# MSPM0G150X register map
Vendor: Texas Instruments; File version: This preliminary header file does not have a version number - build date: 2024-04-29 21:43:54
CPU: CM0 r0p1, little endian, MPU, no FPU, 3 interrupt priority bits
Registers are 32-bit, read-write, reset 0x0 unless marked. A register's access mark holds for its fields unless they carry their own. Offsets are from the block's base; [hi:lo] are bit positions; lines under a group give offsets from that group; {n}, {i} and the like mark numbered series; 'fields as' and 'values as' point back to an identical list.

## RTC — PERIPHERALREGION
Base 0x40094000
0x444 RTC_FPUB_0 — Publisher Port 0
  [3:0] CHANID — 0 = disconnected. 1-15 = connected to channelID = CHANID.
    0=UNCONNECTED (A value of 0 specifies that the event is not connected)
{0x800+0x18*i} RTC_GPRCM[{i}] (i=0..0) group
  0x00 RTC_PWREN — Power enable
    [0] ENABLE — Enable the power
      0=DISABLE (Disable Power); 1=ENABLE (Enable Power)
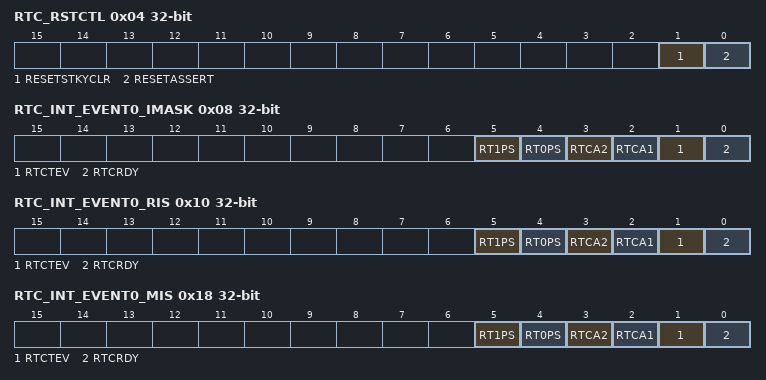
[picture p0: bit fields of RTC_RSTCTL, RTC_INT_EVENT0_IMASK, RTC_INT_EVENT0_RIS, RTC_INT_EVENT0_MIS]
  0x04 RTC_RSTCTL wo — Reset Control
    [1] RESETSTKYCLR — Clear the RESETSTKY bit in the STAT register
      0=NOP (Writing 0 has no effect); 1=CLR (Clear reset sticky bit)
    [0] RESETASSERT — Assert reset to the peripheral
      0=NOP (Writing 0 has no effect); 1=ASSERT (Assert reset)
  0x08 RTC_CLKCFG — Peripheral Clock Configuration Register
    [8] BLOCKASYNC — Async Clock Request is blocked from starting SYSOSC or forcing bus clock to 32MHz
      0=DISABLE (Not block async clock request); 1=ENABLE (Block async clock request)
  0x14 RTC_STAT ro — Status Register
    [16] RESETSTKY — This bit indicates, if the peripheral was reset, since this bit was cleared by RESETSTKYCLR in the RSTCTL register
      0=NORES (The peripheral has not been reset since this bit was last cleared by RESETSTKYCLR in the RSTCTL register); 1=RESET (The peripheral was reset since the last bit clear)
0x1004 RTC_CLKSEL ro — Clock Select for Ultra Low Power peripherals
  [1] LFCLK_SEL — Selects LFCLK as clock source if enabled
    0=DISABLE (LFCLK is disabled as clock source); 1=ENABLE (LFCLK is enabled as clock source)
{0x1020+0x2C*i} RTC_INT_EVENT0[{i}] (i=0..0) group
  0x00 RTC_INT_EVENT0_IIDX ro — Interrupt Index Register
    [7:0] STAT — Interrupt index status
      0=NO_INTR (No interrupt pending); 1=RTCRDY (RTC-Ready interrupt; Interrupt flag: RTCRDY); 2=RTCTEV (Time-Event interrupt; Interrupt flag: RTCTEV); 3=RTCA1 (Alarm-1 interrupt; Interrupt flag: RTCA1); 4=RTCA2 (Alarm-2 interrupt; Interrupt flag: RTCA2); 5=RT0PS (Prescaler-0 interrupt; Interrupt flag: RT0PS); 6=RT1PS (Prescaler-1 interrupt; Interrupt flag: RT1PS)
  0x08 RTC_INT_EVENT0_IMASK — Interrupt mask
    [all] fields
      0=CLR (Clear Interrupt Mask); 1=SET (Set Interrrupt Mask)
    [5] RT1PS — Enable Prescaler-1 interrupt
    [4] RT0PS — Enable Prescaler-0 interrupt
    [3] RTCA2 — Enable Alarm-2 interrupt
    [2] RTCA1 — Enable Alarm-1 interrupt
    [1] RTCTEV — Enable Time-Event interrupt
    [0] RTCRDY — Enable RTC-Ready interrupt
  0x10 RTC_INT_EVENT0_RIS ro — Raw interrupt status
    [all] fields
      0=CLR (Interrupt did not occur); 1=SET (Interrupt occured)
    [5] RT1PS — Raw Prescaler-1 interrupt status
    [4] RT0PS — Raw Prescaler-0 interrupt status
    [3] RTCA2 — Raw Alarm-2 interrupts status
    [2] RTCA1 — Raw Alarm-1 interrupt status
    [1] RTCTEV — Raw Time-Event interrupt status
    [0] RTCRDY — Raw RTC-Ready interrupts status
  0x18 RTC_INT_EVENT0_MIS ro — Masked interrupt status
    [all] fields
      0=CLR (Interrupt did not occur); 1=SET (Interrupt occured)
    [5] RT1PS — Masked Prescaler-1 interrupt status
    [4] RT0PS — Masked Prescaler-0 interrupt status
    [3] RTCA2 — Masked Alarm-2 interrupt status
    [2] RTCA1 — Masked Alarm-1 interrupt status
    [1] RTCTEV — Masked Time-Event interrupt status
    [0] RTCRDY — Masked RTC-Ready interrupt status
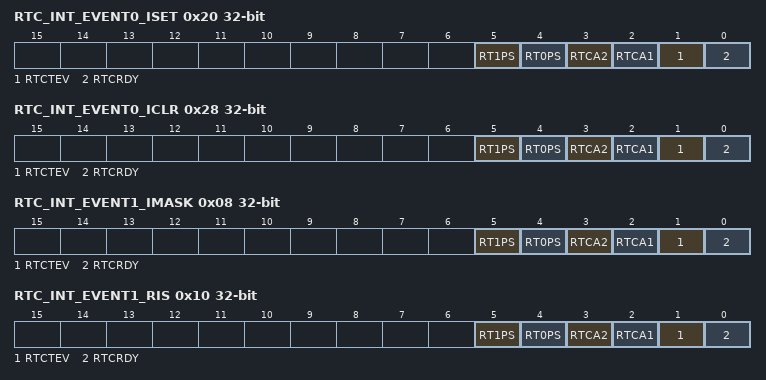
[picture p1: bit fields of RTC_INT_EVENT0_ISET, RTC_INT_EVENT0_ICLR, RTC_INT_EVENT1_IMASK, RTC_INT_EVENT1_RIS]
  0x20 RTC_INT_EVENT0_ISET wo — Interrupt set
    [all] fields
      0=CLR (Writing 0 has no effect); 1=SET (Set Interrupt)
    [5] RT1PS — Set Prescaler-1 interrupt
    [4] RT0PS — Set Prescaler-0 interrupt
    [3] RTCA2 — Set Alarm-2 interrupt
    [2] RTCA1 — Set Alarm-1 interrupt
    [1] RTCTEV — Set Time-Event interrupt
    [0] RTCRDY — Set RTC-Ready interrupt
  0x28 RTC_INT_EVENT0_ICLR wo — Interrupt clear
    [all] fields
      0=CLR (Writing 0 has no effect); 1=SET (Clear Interrupt)
    [5] RT1PS — Clear Prescaler-1 interrupt
    [4] RT0PS — Clear Prescaler-0 interrupt
    [3] RTCA2 — Clear Alarm-2 interrupt
    [2] RTCA1 — Clear Alarm-1 interrupt
    [1] RTCTEV — Clear Time-Event interrupt
    [0] RTCRDY — Clear RTC-Ready interrupt
{0x1050+0x2C*i} RTC_INT_EVENT1[{i}] (i=0..0) group
  0x00 RTC_INT_EVENT1_IIDX ro — Interrupt Index Register
    fields as RTC_INT_EVENT0[0].RTC_INT_EVENT0_IIDX
  0x08 RTC_INT_EVENT1_IMASK — Interrupt mask
    fields as RTC_INT_EVENT0[0].RTC_INT_EVENT0_IMASK
  0x10 RTC_INT_EVENT1_RIS ro — Raw interrupt status
    fields as RTC_INT_EVENT0[0].RTC_INT_EVENT0_RIS
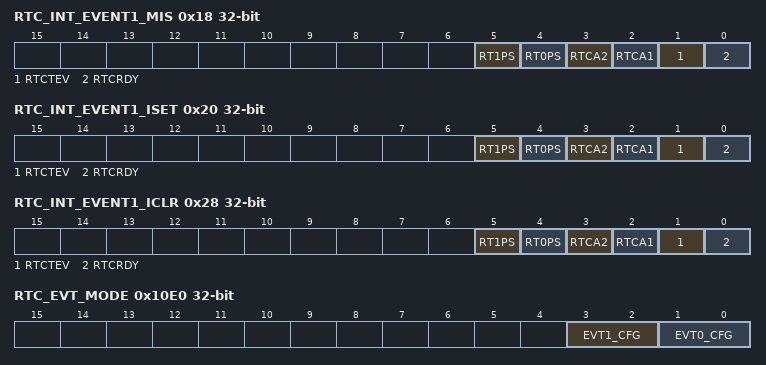
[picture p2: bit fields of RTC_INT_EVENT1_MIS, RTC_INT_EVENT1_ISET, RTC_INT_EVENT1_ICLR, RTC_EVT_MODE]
  0x18 RTC_INT_EVENT1_MIS ro — Masked interrupt status
    fields as RTC_INT_EVENT0[0].RTC_INT_EVENT0_MIS
  0x20 RTC_INT_EVENT1_ISET wo — Interrupt set
    fields as RTC_INT_EVENT0[0].RTC_INT_EVENT0_ISET
  0x28 RTC_INT_EVENT1_ICLR wo — Interrupt clear
    [5] RT1PS — Clear Prescaler-1 interrupt
      0=CLR (Clear Interrupt Mask); 1=SET (Set Interrrupt Mask)
    [4] RT0PS — Clear Prescaler-0 interrupt
      0=CLR (Clear Interrupt Mask); 1=SET (Set Interrrupt Mask)
    [3] RTCA2 — Clear Alarm-2 interrupt
      0=CLR (Clear Interrupt Mask); 1=SET (Set Interrrupt Mask)
    [2] RTCA1 — Clear Alarm-1 interrupt
      0=CLR (Clear Interrupt Mask); 1=SET (Set Interrrupt Mask)
    [1] RTCTEV — Clear Time-Event interrupt
      0=CLR (Clear Interrupt Mask); 1=SET (Set Interrrupt Mask)
    [0] RTCRDY — Clear RTC-Ready interrupt
      0=CLR (Clear Interrupt Mask); 1=SET (Clear Interrupt)
0x10E0 RTC_EVT_MODE — Event Mode
  [3:2] EVT1_CFG ro — Event line mode 1 select
    0=DISABLE (The interrupt or event line is disabled.); 1=SOFTWARE (The interrupt or event line is in software mode. The software ISR clears the associated RIS flag.); 2=HARDWARE (The interrupt or event line is in hardware mode. The hardware (another module) clears automatically the associated RIS flag.)
  [1:0] EVT0_CFG ro — Event line mode 0 select
    values as EVT1_CFG
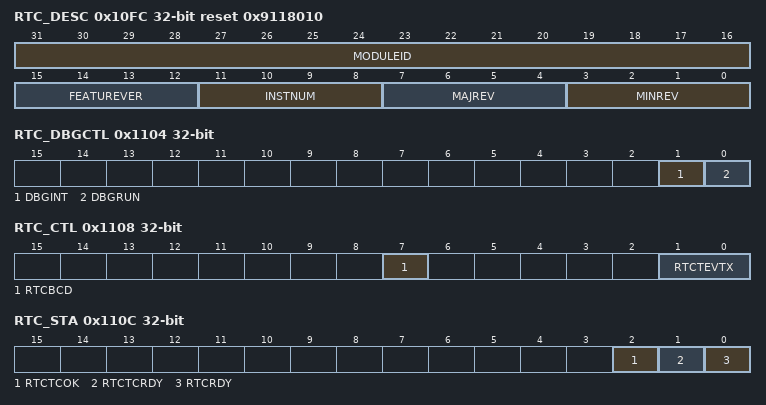
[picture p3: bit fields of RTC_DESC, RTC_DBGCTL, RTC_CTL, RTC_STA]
0x10FC RTC_DESC ro reset 0x9118010 — RTC Descriptor Register
  [31:16] MODULEID — Module identifier. This ID is unique for each module. 0x0911 = Module ID of the RTC Module
  [15:12] FEATUREVER — Feature set of this module. Differentiates the complexity of the actually instantiated module if there are differences.
  [11:8] INSTNUM — Instantiated version. Describes which instance of the module accessed.
    0=INST0 (This is the default, if there is only one instance - like for SSIM)
  [7:4] MAJREV — Major revision. This number holds the module revision and is incremented by the module developers. n = Major version (see device-specific data sheet)
  [3:0] MINREV — Minor revision. This number holds the module revision and is incremented by the module developers. n = Minor module revision (see device-specific data sheet)
0x1100 RTC_CLKCTL — RTC Clock Control Register
  [31] MODCLKEN — This bit enables the supply of the 32kHz clock to the RTC. It will not power-up the 32kHz crystal oscillator this needs to be done in the Clock System Module.
    0=DISABLE (32kHz clock is not supplied to the RTC.); 1=ENABLE (32kHz clock is supplied to the RTC.)
0x1104 RTC_DBGCTL — RTC Module Debug Control Register
  [1] DBGINT — Debug Interrupt Enable.
    0=OFF (Interrupts of the module will not be captured anymore if CPU is in debug state. Which means no update to the RTCRIS, RTCMISC and RTCIIDX register.); 1=ON (Interrupts are enabled in debug mode. Interrupt requests are signaled to the interrupt controller. If the flags are required by software (polling mode) the DGBINT bit need to be set to 1.)
  [0] DBGRUN — Debug Run.
    0=HALT (Counter is halted if CPU is in debug state.); 1=RUN (Continue to operate normally ignoring the debug state of the CPU.)
0x1108 RTC_CTL — RTC Control Register
  [7] RTCBCD — Real-time clock BCD select. Selects BCD counting for real-time clock.
    0=BINARY (Binary code selected); 1=BCD (Binary coded decimal (BCD) code selected)
  [1:0] RTCTEVTX — Real-time clock time event.
    0=MINUTE (Minute changed.); 1=HOUR (Hour changed.); 2=MIDNIGHT (Every day at midnight (00:00).); 3=NOON (Every day at noon (12:00).)
0x110C RTC_STA ro — RTC Status Register
  [2] RTCTCOK — Real-time clock temperature compensation write OK. This is a read-only bit that indicates if the write to RTCTCMP is successful or not.
    0=NOT_OK (Write to RTCTCMPx is unsuccessful); 1=OK (Write to RTCTCMPx is successful)
  [1] RTCTCRDY — Real-time clock temperature compensation ready. This is a read only bit that indicates when the RTCTCMPx can be written. Write to RTCTCMPx should be avoided when RTCTCRDY is reset.
    0=NOT_READY (Real-time clock temperature compensation not ready); 1=READY (Real-time clock temperature compensation ready)
  [0] RTCRDY — Real-time clock ready. This bit indicates when the real-time clock time values are safe for reading.
    0=NOT_READY (RTC time values in transition); 1=READY (RTC time values safe for reading)
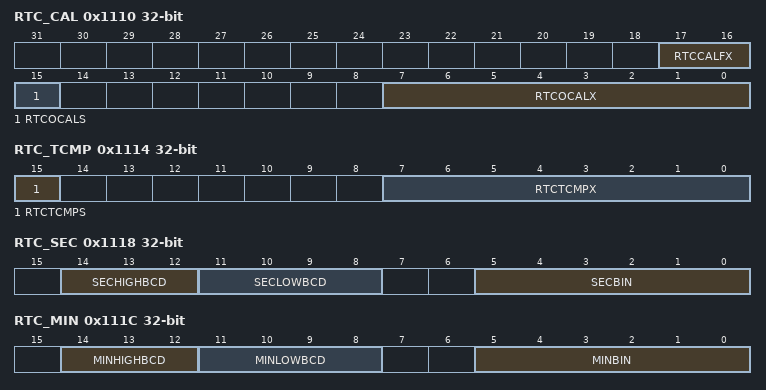
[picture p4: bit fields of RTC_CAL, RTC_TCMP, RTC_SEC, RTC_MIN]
0x1110 RTC_CAL — RTC Clock Offset Calibration Register
  [17:16] RTCCALFX — Real-time clock calibration frequency. Selects frequency output to RTC_OUT pin for calibration measurement. The corresponding port must be configured for the peripheral module function.
    0=OFF (No frequency output to RTC_OUT pin); 1=F512HZ (512 Hz); 2=F256HZ (256 Hz); 3=F1HZ (1 Hz)
  [15] RTCOCALS — Real-time clock offset error calibration sign. This bit decides the sign of offset error calibration.
    0=DOWN (Down calibration. Frequency adjusted down.); 1=UP (Up calibration. Frequency adjusted up.)
  [7:0] RTCOCALX — Real-time clock offset error calibration. Each LSB represents approximately +1ppm (RTCOCALXS = 1) or -1ppm (RTCOCALXS = 0) adjustment in frequency. Maximum effective calibration value is +/-240ppm. Excess values written above +/-240ppm will be ignored by hardware.
0x1114 RTC_TCMP — RTC Temperature Compensation Register
  [15] RTCTCMPS — Real-time clock temperature compensation sign. This bit decides the sign of temperature compensation.
    values as RTC_CAL.RTCOCALS
  [7:0] RTCTCMPX — Real-time clock temperature compensation. Value written into this register is used for temperature compensation of RTC. Each LSB represents approximately +1ppm (RTCTCMPS = 1) or -1ppm (RTCTCMPS = 0) adjustment in frequency. Maximum effective calibration value is +/-240ppm. Excess values written above +/-240ppm are ignored by hardware. Reading from RTCTCMP register at any time returns the cumulative value which is the signed addition of RTCOCALx and RTCTCMPX values, and the updated sign bit (RTCTCMPS) of the addition result.
0x1118 RTC_SEC (reset mask 0xFFFF80C0) — RTC Seconds Register - Calendar Mode With Binary / BCD Format
  [14:12] SECHIGHBCD — Seconds BCD high digit (0 to 5). If RTCBCD=0 write to these bits will be ignored and read give the value 0.
  [11:8] SECLOWBCD — Seconds BCD low digit (0 to 9). If RTCBCD=0 write to these bits will be ignored and read give the value 0.
  [5:0] SECBIN — Seconds Binary (0 to 59). If RTCBCD=1 write to these bits will be ignored and read give the value 0.
0x111C RTC_MIN (reset mask 0xFFFF80C0) — RTC Minutes Register - Calendar Mode With Binary / BCD Format
  [14:12] MINHIGHBCD — Minutes BCD high digit (0 to 5). If RTCBCD=0 write to these bits will be ignored and read give the value 0.
  [11:8] MINLOWBCD — Minutes BCD low digit (0 to 9). If RTCBCD=0 write to these bits will be ignored and read give the value 0.
  [5:0] MINBIN — Minutes Binary (0 to 59). If RTCBCD=1 write to these bits will be ignored and read give the value 0.
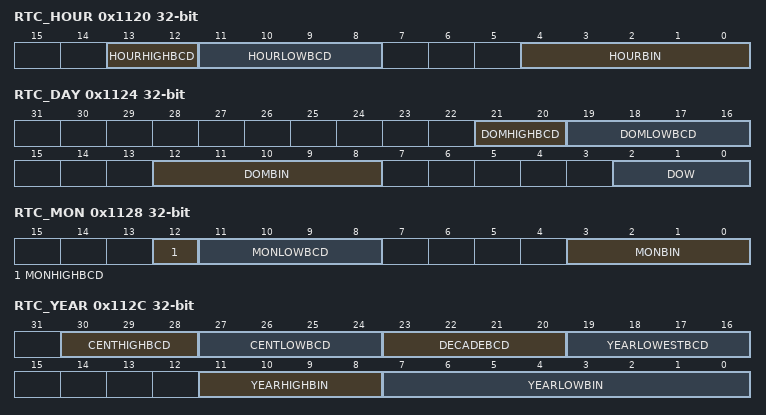
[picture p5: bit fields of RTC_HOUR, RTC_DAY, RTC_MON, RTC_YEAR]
0x1120 RTC_HOUR (reset mask 0xFFFFC0E0) — RTC Hours Register - Calendar Mode With Binary / BCD Format
  [13:12] HOURHIGHBCD — Hours BCD high digit (0 to 2). If RTCBCD=0 write to these bits will be ignored and read give the value 0.
  [11:8] HOURLOWBCD — Hours BCD low digit (0 to 9). If RTCBCD=0 write to these bits will be ignored and read give the value 0.
  [4:0] HOURBIN — Hours Binary (0 to 23). If RTCBCD=1 write to these bits will be ignored and read give the value 0.
0x1124 RTC_DAY (reset mask 0xFFC0E0F8) — RTC Day Of Week / Month Register - Calendar Mode With Binary / BCD Format
  [21:20] DOMHIGHBCD — Day of month BCD high digit (0 to 3). If RTCBCD=0 write to these bits will be ignored and read give the value 0.
  [19:16] DOMLOWBCD — Day of month BCD low digit (0 to 9). If RTCBCD=0 write to these bits will be ignored and read give the value 0.
  [12:8] DOMBIN — Day of month Binary (1 to 28, 29, 30, 31). If RTCBCD=1 write to these bits will be ignored and read give the value 0.
  [2:0] DOW — Day of week (0 to 6). These bits are valid if RTCBCD=1 or RTCBCD=0.
0x1128 RTC_MON (reset mask 0xFFFFE0F0) — RTC Month Register - Calendar Mode With Binary / BCD Format
  [12] MONHIGHBCD — Month BCD high digit (0 or 1). If RTCBCD=0 write to these bits will be ignored and read give the value 0.
  [11:8] MONLOWBCD — Month BCD low digit (0 to 9). If RTCBCD=0 write to these bits will be ignored and read give the value 0.
  [3:0] MONBIN — Month Binary (1 to 12). If RTCBCD=1 write to these bits will be ignored and read give the value 0.
0x112C RTC_YEAR (reset mask 0x8000F000) — RTC Year Register - Calendar Mode With Binary / BCD Format
  [30:28] CENTHIGHBCD — Century BCD high digit (0 to 4). If RTCBCD=0 write to these bits will be ignored and read give the value 0.
  [27:24] CENTLOWBCD — Century BCD low digit (0 to 9). If RTCBCD=0 write to these bits will be ignored and read give the value 0.
  [23:20] DECADEBCD — Decade BCD (0 to 9). If RTCBCD=0 write to these bits will be ignored and read give the value 0.
  [19:16] YEARLOWESTBCD — Year BCD lowest digit (0 to 9). If RTCBCD=0 write to these bits will be ignored and read give the value 0.
  [11:8] YEARHIGHBIN — Year Binary high byte. Valid values for Year are 0 to 4095. If RTCBCD=1 write to these bits will be ignored and read give the value 0.
  [7:0] YEARLOWBIN — Year Binary low byte. Valid values for Year are 0 to 4095. If RTCBCD=1 write to these bits will be ignored and read give the value 0.
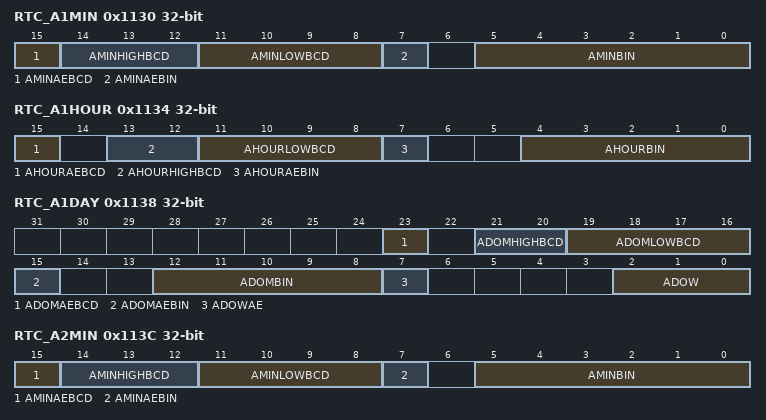
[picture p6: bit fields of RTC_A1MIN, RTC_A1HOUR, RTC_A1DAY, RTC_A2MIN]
0x1130 RTC_A1MIN — RTC Minute Alarm Register - Calendar Mode With Binary / BCD Format
  [15] AMINAEBCD — Alarm Minutes BCD enable. If RTCBCD=0 this bit is always 0. Write to this bit will be ignored.
    0=DISABLE (Alarm disabled); 1=ENABLE (Alarm enabled)
  [14:12] AMINHIGHBCD — Alarm Minutes BCD high digit (0 to 5). If RTCBCD=0 write to these bits will be ignored and read give the value 0.
  [11:8] AMINLOWBCD — Alarm Minutes BCD low digit (0 to 9). If RTCBCD=0 write to these bits will be ignored and read give the value 0.
  [7] AMINAEBIN — Alarm Minutes Binary enable. If RTCBCD=1 this bit is always 0. Write to this bit will be ignored.
    0=DISABLE (Alarm disabled); 1=ENABLE (Alarm enabled)
  [5:0] AMINBIN — Alarm Minutes Binary (0 to 59). If RTCBCD=1 write to these bits will be ignored and read give the value 0.
0x1134 RTC_A1HOUR — RTC Hours Alarm Register - Calendar Mode With Binary / BCD Format
  [15] AHOURAEBCD — Alarm Hours BCD enable. If RTCBCD=0 this bit is always 0. Write to this bit will be ignored.
    0=DISABLE (Alarm disabled); 1=ENABLE (Alarm enabled)
  [13:12] AHOURHIGHBCD — Alarm Hours BCD high digit (0 to 2). If RTCBCD=0 write to these bits will be ignored and read give the value 0..
  [11:8] AHOURLOWBCD — Alarm Hours BCD low digit (0 to 9). If RTCBCD=0 write to these bits will be ignored and read give the value 0.
  [7] AHOURAEBIN — Alarm Hours Binary enable. If RTCBCD=1 this bit is always 0. Write to this bit will be ignored.
    0=DISABLE (Alarm disabled); 1=ENABLE (Alarm enabled)
  [4:0] AHOURBIN — Alarm Hours Binary (0 to 23). If RTCBCD=1 write to these bits will be ignored and read give the value 0.
0x1138 RTC_A1DAY — RTC Alarm Day Of Week / Month Register - Calendar Mode With Binary / BCD Format
  [23] ADOMAEBCD — Alarm Day of month BCD enable. If RTCBCD=0 this bit is always 0. Write to this bit will be ignored.
    0=DISABLE (Alarm disabled); 1=ENABLE (Alarm enabled)
  [21:20] ADOMHIGHBCD — Alarm Day of month BCD high digit (0 to 3). If RTCBCD=0 write to these bits will be ignored and read give the value 0.
  [19:16] ADOMLOWBCD — Alarm Day of month BCD low digit (0 to 9). If RTCBCD=0 write to these bits will be ignored and read give the value 0.
  [15] ADOMAEBIN — Alarm Day of month Binary enable. If RTCBCD=1 this bit is always 0. Write to this bit will be ignored.
    0=DISABLE (Alarm disabled); 1=ENABLE (Alarm enabled)
  [12:8] ADOMBIN — Alarm Day of month Binary (1 to 28, 29, 30, 31) If RTCBCD=1 write to these bits will be ignored and read give the value 0.
  [7] ADOWAE — Alarm Day of week enable. This bit are valid if RTCBCD=1 or RTCBCD=0.
    0=DISABLE (Alarm disabled); 1=ENABLE (Alarm enabled)
  [2:0] ADOW — Alarm Day of week (0 to 6). These bits are valid if RTCBCD=1 or RTCBCD=0.
0x113C RTC_A2MIN — RTC Minute Alarm Register - Calendar Mode With Binary / BCD Format
  fields as RTC_A1MIN
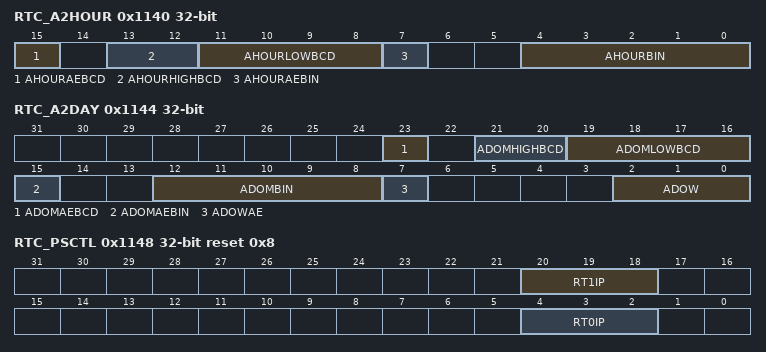
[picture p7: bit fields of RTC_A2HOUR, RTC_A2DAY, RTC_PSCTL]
0x1140 RTC_A2HOUR — RTC Hours Alarm Register - Calendar Mode With Binary / BCD Format
  fields as RTC_A1HOUR
0x1144 RTC_A2DAY — RTC Alarm Day Of Week / Month Register - Calendar Mode With Binary / BCD Format
  fields as RTC_A1DAY
0x1148 RTC_PSCTL reset 0x8 — RTC Prescale Timer 0/1 Control Register
  [20:18] RT1IP — Prescale timer 1 interrupt interval
    0=DIV2 (Divide by 2 - 15.6 millisecond interval); 1=DIV4 (Divide by 4 - 31.2 millisecond interval); 2=DIV8 (Divide by 8 - 62.5 millisecond interval); 3=DIV16 (Divide by 16 - 125 millisecond interval); 4=DIV32 (Divide by 32 - 250 millisecond interval); 5=DIV64 (Divide by 64 - 500 millisecond interval); 6=DIV128 (Divide by 128 - 1 second interval); 7=DIV256 (Divide by 256 - 2 second interval)
  [4:2] RT0IP — Prescale timer 0 interrupt interval
    2=DIV8 (Divide by 8 - 244 microsecond interval); 3=DIV16 (Divide by 16 - 488 microsecond interval); 4=DIV32 (Divide by 32 - 976 microsecond interval); 5=DIV64 (Divide by 64 - 1.95 millisecond interval); 6=DIV128 (Divide by 128 - 3.90 millisecond interval); 7=DIV256 (Divide by 256 - 7.81 millisecond interval)
